# M2354 register map
File version: 1.0
Registers are 32-bit, read-write, reset 0x0 unless marked. A register's access mark holds for its fields unless they carry their own. Offsets are from the block's base; [hi:lo] are bit positions; {n}, {i} and the like mark numbered series; 'fields as' and 'values as' point back to an identical list.

## SYS (part 2 of 2) — SYS Register Map
Base 0x40000000
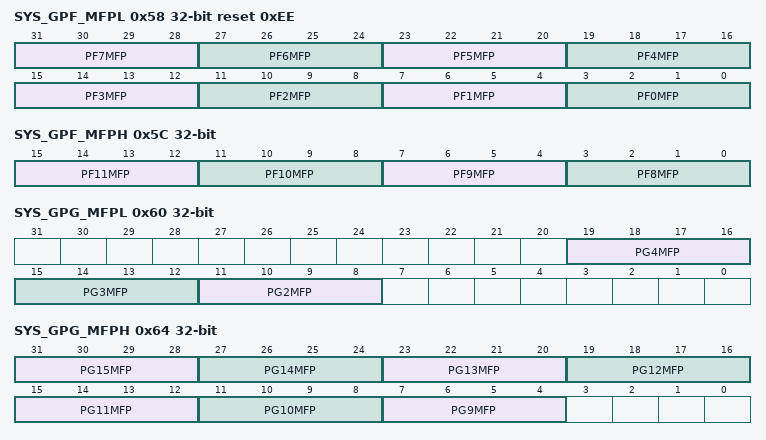
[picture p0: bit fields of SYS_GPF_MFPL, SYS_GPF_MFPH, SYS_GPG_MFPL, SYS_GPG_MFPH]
0x58 SYS_GPF_MFPL reset 0xEE — GPIOF Low Byte Multiple Function Control Register
  [31:28] PF7MFP — PF.7 Multi-function Pin Selection
    0=PF.7; 2=EBI_ADR18; 3=SC0_DAT; 4=I2S0_DO; 5=SPI0_MISO; 6=UART4_TXD; 10=TAMPER1
  [27:24] PF6MFP — PF.6 Multi-function Pin Selection
    0=PF.6; 2=EBI_ADR19; 3=SC0_CLK; 4=I2S0_LRCK; 5=SPI0_MOSI; 6=UART4_RXD; 7=EBI_nCS0; 9=SPI3_I2SMCLK; 10=TAMPER0
  [23:20] PF5MFP — PF.5 Multi-function Pin Selection
    0=PF.5; 2=UART2_RXD; 4=UART2_nCTS; 7=EPWM0_CH0; 8=BPWM0_CH4; 9=EPWM0_SYNC_OUT; 10=X32_IN; 11=EADC0_ST
  [19:16] PF4MFP — PF.4 Multi-function Pin Selection
    0=PF.4; 2=UART2_TXD; 4=UART2_nRTS; 7=EPWM0_CH1; 8=BPWM0_CH5; 10=X32_OUT
  [15:12] PF3MFP — PF.3 Multi-function Pin Selection
    0=PF.3; 2=EBI_nCS0; 3=UART0_TXD; 4=I2C0_SCL; 10=XT1_IN; 11=BPWM1_CH0
  [11:8] PF2MFP — PF.2 Multi-function Pin Selection
    0=PF.2; 2=EBI_nCS1; 3=UART0_RXD; 4=I2C0_SDA; 5=QSPI0_CLK; 10=XT1_OUT; 11=BPWM1_CH1
  [7:4] PF1MFP — PF.1 Multi-function Pin Selection
    0=PF.1; 2=UART1_RXD; 3=I2C1_SDA; 4=UART0_RXD; 12=BPWM1_CH1; 14=ICE_CLK
  [3:0] PF0MFP — PF.0 Multi-function Pin Selection
    0=PF.0; 2=UART1_TXD; 3=I2C1_SCL; 4=UART0_TXD; 12=BPWM1_CH0; 14=ICE_DAT
0x5C SYS_GPF_MFPH — GPIOF High Byte Multiple Function Control Register
  [15:12] PF11MFP — PF.11 Multi-function Pin Selection
    0=PF.11; 2=EBI_ADR14; 3=SPI2_MOSI; 6=UART5_TXD; 10=TAMPER5; 12=TM5; 13=TM3
  [11:8] PF10MFP — PF.10 Multi-function Pin Selection
    0=PF.10; 2=EBI_ADR15; 3=SC0_nCD; 4=I2S0_BCLK; 5=SPI0_I2SMCLK; 6=UART5_RXD; 10=TAMPER4
  [7:4] PF9MFP — PF.9 Multi-function Pin Selection
    0=PF.9; 2=EBI_ADR16; 3=SC0_PWR; 4=I2S0_MCLK; 5=SPI0_SS; 6=UART5_nRTS; 10=TAMPER3
  [3:0] PF8MFP — PF.8 Multi-function Pin Selection
    0=PF.8; 2=EBI_ADR17; 3=SC0_RST; 4=I2S0_DI; 5=SPI0_CLK; 6=UART5_nCTS; 10=TAMPER2
0x60 SYS_GPG_MFPL — GPIOG Low Byte Multiple Function Control Register
  [19:16] PG4MFP — PG.4 Multi-function Pin Selection
    0=PG.4; 2=EBI_ADR13; 3=SPI2_MISO; 12=TM4; 13=TM2; 15=LCD_SEG37
  [15:12] PG3MFP — PG.3 Multi-function Pin Selection
    0=PG.3; 2=EBI_ADR12; 3=SPI2_CLK; 4=I2C0_SMBSUS; 5=I2C1_SDA; 13=TM1; 15=LCD_SEG38
  [11:8] PG2MFP — PG.2 Multi-function Pin Selection
    0=PG.2; 2=EBI_ADR11; 3=SPI2_SS; 4=I2C0_SMBAL; 5=I2C1_SCL; 13=TM0; 15=LCD_SEG39
0x64 SYS_GPG_MFPH — GPIOG High Byte Multiple Function Control Register
  [31:28] PG15MFP — PG.15 Multi-function Pin Selection
    0=PG.15; 13=LCD_SEG15; 14=CLKO; 15=EADC0_ST
  [27:24] PG14MFP — PG.14 Multi-function Pin Selection
    0=PG.14; 2=EBI_AD5; 12=BPWM0_CH0; 15=LCD_SEG16
  [23:20] PG13MFP — PG.13 Multi-function Pin Selection
    0=PG.13; 2=EBI_AD4; 12=BPWM0_CH1; 15=LCD_SEG17
  [19:16] PG12MFP — PG.12 Multi-function Pin Selection
    0=PG.12; 2=EBI_AD3; 12=BPWM0_CH2; 15=LCD_SEG18
  [15:12] PG11MFP — PG.11 Multi-function Pin Selection
    0=PG.11; 2=EBI_AD2; 12=BPWM0_CH3; 15=LCD_SEG19
  [11:8] PG10MFP — PG.10 Multi-function Pin Selection
    0=PG.10; 2=EBI_AD1; 12=BPWM0_CH4; 15=LCD_SEG20
  [7:4] PG9MFP — PG.9 Multi-function Pin Selection
    0=PG.9; 2=EBI_AD0; 12=BPWM0_CH5; 15=LCD_SEG21
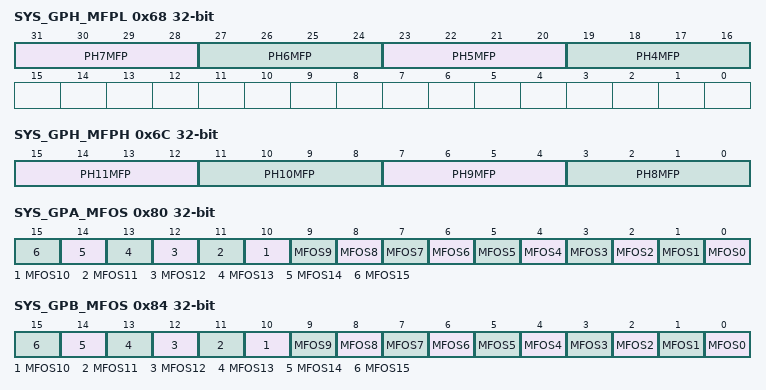
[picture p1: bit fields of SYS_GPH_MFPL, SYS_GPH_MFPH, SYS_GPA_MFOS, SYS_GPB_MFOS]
0x68 SYS_GPH_MFPL — GPIOH Low Byte Multiple Function Control Register
  [31:28] PH7MFP — PH.7 Multi-function Pin Selection
    0=PH.7; 2=EBI_ADR0; 3=SPI1_SS; 15=LCD_SEG33
  [27:24] PH6MFP — PH.6 Multi-function Pin Selection
    0=PH.6; 2=EBI_ADR1; 3=SPI1_CLK; 15=LCD_SEG34
  [23:20] PH5MFP — PH.5 Multi-function Pin Selection
    0=PH.5; 2=EBI_ADR2; 3=SPI1_MOSI; 15=LCD_SEG35
  [19:16] PH4MFP — PH.4 Multi-function Pin Selection
    0=PH.4; 2=EBI_ADR3; 3=SPI1_MISO; 15=LCD_SEG36
0x6C SYS_GPH_MFPH — GPIOH High Byte Multiple Function Control Register
  [15:12] PH11MFP — PH.11 Multi-function Pin Selection
    0=PH.11; 2=EBI_AD15; 3=QSPI0_MOSI1; 7=UART4_RXD; 8=UART0_RXD; 11=EPWM0_CH5; 15=LCD_SEG1
  [11:8] PH10MFP — PH.10 Multi-function Pin Selection
    0=PH.10; 2=EBI_AD14; 3=QSPI0_MISO1; 4=SC2_nCD; 5=I2S0_LRCK; 6=SPI1_I2SMCLK; 7=UART4_TXD; 8=UART0_TXD; 15=LCD_SEG2
  [7:4] PH9MFP — PH.9 Multi-function Pin Selection
    0=PH.9; 2=EBI_AD13; 3=QSPI0_SS; 4=SC2_RST; 5=I2S0_DO; 6=SPI1_SS; 7=UART3_nCTS; 8=I2C1_SMBSUS; 9=I2C2_SDA; 10=UART1_RXD; 15=LCD_SEG3
  [3:0] PH8MFP — PH.8 Multi-function Pin Selection
    0=PH.8; 2=EBI_AD12; 3=QSPI0_CLK; 4=SC2_PWR; 5=I2S0_DI; 6=SPI1_CLK; 7=UART3_nRTS; 8=I2C1_SMBAL; 9=I2C2_SCL; 10=UART1_TXD; 15=LCD_SEG4
0x80 SYS_GPA_MFOS — GPIOA Multiple Function Output Select Register
  [all] fields
    0=Multiple function pin output mode type is Push-pull mode; 1=Multiple function pin output mode type is Open-drain mode
  [n] MFOS{n} (n=0..15) — GPIOA-h Pin[n] Multiple Function Pin Output Mode Select. This bit used to select multiple function pin output mode type for Px.n pin.
0x84 SYS_GPB_MFOS — GPIOB Multiple Function Output Select Register
  fields as SYS_GPA_MFOS
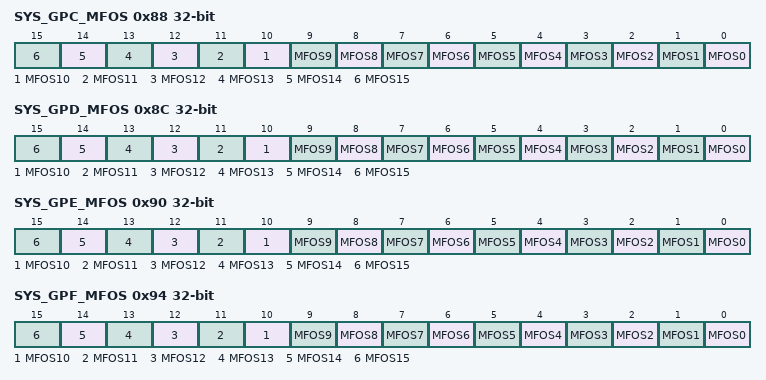
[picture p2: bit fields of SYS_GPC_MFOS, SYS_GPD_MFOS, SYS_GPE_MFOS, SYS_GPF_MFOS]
0x88 SYS_GPC_MFOS — GPIOC Multiple Function Output Select Register
  fields as SYS_GPA_MFOS
0x8C SYS_GPD_MFOS — GPIOD Multiple Function Output Select Register
  fields as SYS_GPA_MFOS
0x90 SYS_GPE_MFOS — GPIOE Multiple Function Output Select Register
  fields as SYS_GPA_MFOS
0x94 SYS_GPF_MFOS — GPIOF Multiple Function Output Select Register
  fields as SYS_GPA_MFOS
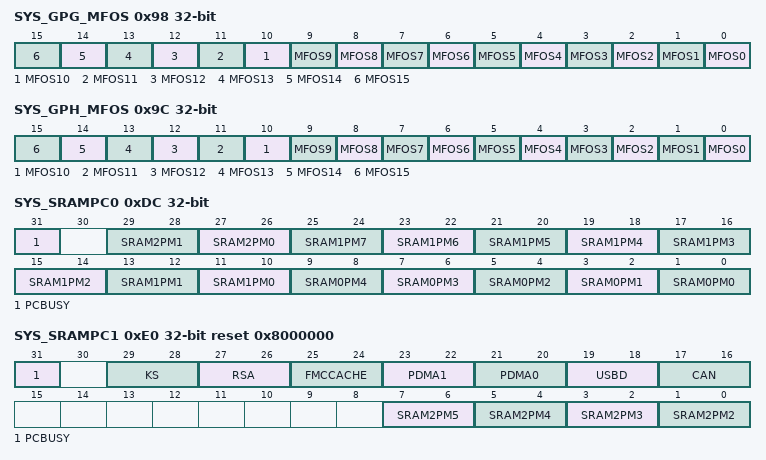
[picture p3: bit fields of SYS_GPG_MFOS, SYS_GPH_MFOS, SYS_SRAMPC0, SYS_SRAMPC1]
0x98 SYS_GPG_MFOS — GPIOG Multiple Function Output Select Register
  fields as SYS_GPA_MFOS
0x9C SYS_GPH_MFOS — GPIOH Multiple Function Output Select Register
  fields as SYS_GPA_MFOS
0xA0 SYS_VTORSET — VTOR Setting Register
  [31:10] VTORSET — VTOR Setting After SPD Wakeup (Write Protect). This is the register to set the address of vector table after chip is waked up from SPD mode. The value will be loaded to Vector Table Offset Register, which is at the address 0xE000ED08, when chip wake up from SPD mode. Note: These bits are write protected. Refer to the SYS_REGLCTL register.
0xC0 SYS_SRAMICTL — System SRAM Parity Error Interrupt Enable Control Register
  [0] PERRIEN — SRAM Parity Check Error Interrupt Enable Bit
    0=SRAM parity check error interrupt Disabled; 1=SRAM parity check error interrupt Enabled
0xC4 SYS_SRAMSTS ro (reset mask 0xFFFFFFF0) — System SRAM Parity Check Status Register
  [0] PERRIF — SRAM Parity Check Error Flag. This bit indicates the System SRAM parity error occurred. Write 1 to clear this to 0. Note: The default value depends on the content of SRAM. It is better to check this value before use it. If the default value is 1, it shall be cleared first.
    0=No System SRAM parity error; 1=System SRAM parity error occur
0xC8 SYS_SRAMEADR ro — System SRAM Parity Error Address Register
  [31:0] ERRADDR — System SRAM Parity Error Address. This register shows system SRAM parity error byte address.
0xDC SYS_SRAMPC0 — SRAM Power Mode Control Register 0
  [31] PCBUSY ro — Power Changing Busy Flag (Read Only). This bit indicate SRAM power changing.
    0=SRAM power change finish; 1=SRAM power changing
  [29:28] SRAM2PM1 — Bank2 SRAM Power Mode Select 1 (Write Protect). This field can control bank2 sram1 (16k) power mode for range 0x2002_C000 - 0x2002_FFFF. Note 1: These bits are write protected. Refer to the SYS_REGLCTL register. Note 2: Write ignore when PCBUSY is 1.
    0=Normal mode; 1=Retention mode; 2=Power shut down mode
  [27:26] SRAM2PM0 — Bank2 SRAM Power Mode Select 0 (Write Protect). This field can control bank2 sram0 (16k) power mode for range 0x2002_8000 - 0x2002_BFFF. Note 1: These bits are write protected. Refer to the SYS_REGLCTL register. Note 2: Write ignore when PCBUSY is 1.
    0=Normal mode; 1=Retention mode; 2=Power shut down mode
  [25:24] SRAM1PM7 — Bank1 SRAM Power Mode Select 7 (Write Protect). This field can control bank1 sram7 (16k) power mode for range 0x2002_4000 - 0x2002_7FFF. Note 1: These bits are write protected. Refer to the SYS_REGLCTL register. Note 2: Write ignore when PCBUSY is 1.
    0=Normal mode; 1=Retention mode; 2=Power shut down mode
  [23:22] SRAM1PM6 — Bank1 SRAM Power Mode Select 6 (Write Protect). This field can control bank1 sram6 (16k) power mode for range 0x2002_0000 - 0x2002_3FFF. Note 1: These bits are write protected. Refer to the SYS_REGLCTL register. Note 2: Write ignore when PCBUSY is 1.
    0=Normal mode; 1=Retention mode; 2=Power shut down mode
  [21:20] SRAM1PM5 — Bank1 SRAM Power Mode Select 5 (Write Protect). This field can control bank1 sram5 (16k) power mode for range 0x2001_C000 - 0x2001_FFFF. Note 1: These bits are write protected. Refer to the SYS_REGLCTL register. Note 2: Write ignore when PCBUSY is 1.
    0=Normal mode; 1=Retention mode; 2=Power shut down mode
  [19:18] SRAM1PM4 — Bank1 SRAM Power Mode Select 4 (Write Protect). This field can control bank1 sram4 (16k) power mode for range 0x2001_8000 - 0x2001_BFFF. Note 1: These bits are write protected. Refer to the SYS_REGLCTL register. Note 2: Write ignore when PCBUSY is 1.
    0=Normal mode; 1=Retention mode; 2=Power shut down mode
  [17:16] SRAM1PM3 — Bank1 SRAM Power Mode Select 3 (Write Protect). This field can control bank1 sram3 (16k) power mode for range 0x2001_4000 - 0x2001_7FFF. Note 1: These bits are write protected. Refer to the SYS_REGLCTL register. Note 2: Write ignore when PCBUSY is 1.
    0=Normal mode; 1=Retention mode; 2=Power shut down mode
  [15:14] SRAM1PM2 — Bank1 SRAM Power Mode Select 2 (Write Protect). This field can control bank1 sram2 (16k) power mode for range 0x2001_0000 - 0x2001_3FFF. Note 1: These bits are write protected. Refer to the SYS_REGLCTL register. Note 2: Write ignore when PCBUSY is 1.
    0=Normal mode; 1=Retention mode; 2=Power shut down mode
  [13:12] SRAM1PM1 — Bank1 SRAM Power Mode Select 1 (Write Protect). This field can control bank1 sram1 (16k) power mode for range 0x2000_C000 - 0x2000_FFFF. Note 1: These bits are write protected. Refer to the SYS_REGLCTL register. Note 2: Write ignore when PCBUSY is 1.
    0=Normal mode; 1=Retention mode; 2=Power shut down mode
  [11:10] SRAM1PM0 — Bank1 SRAM Power Mode Select 0 (Write Protect). This field can control bank1 sram0 (16k) power mode for range 0x2000_8000 - 0x2000_BFFF. Note 1: These bits are write protected. Refer to the SYS_REGLCTL register. Note 2: Write ignore when PCBUSY is 1.
    0=Normal mode; 1=Retention mode; 2=Power shut down mode
  [9:8] SRAM0PM4 — Bank0 SRAM Power Mode Select 4 (Write Protect). This field can control bank0 sram4 (8k) power mode for range 0x2000_6000 - 0x2000_7FFF. Note 1: These bits are write protected. Refer to the SYS_REGLCTL register. Note 2: Write ignore when PCBUSY is 1.
    0=Normal mode; 1=Retention mode; 2=Power shut down mode
  [7:6] SRAM0PM3 — Bank0 SRAM Power Mode Select 3 (Write Protect). This field can control bank0 sram3 (8k) power mode for range 0x2000_4000 - 0x2000_5FFF. Note 1: These bits are write protected. Refer to the SYS_REGLCTL register. Note 2: Write ignore when PCBUSY is 1.
    0=Normal mode; 1=Retention mode; 2=Power shut down mode
  [5:4] SRAM0PM2 — Bank0 SRAM Power Mode Select 2 (Write Protect). This field can control bank0 sram2 (8k) power mode for range 0x2000_2000 - 0x2000_3FFF. Note 1: These bits are write protected. Refer to the SYS_REGLCTL register. Note 2: Write ignore when PCBUSY is 1.
    0=Normal mode; 1=Retention mode; 2=Power shut down mode
  [3:2] SRAM0PM1 — Bank0 SRAM Power Mode Select 1 (Write Protect). This field can control bank0 sram1 (4k) power mode for range 0x2000_1000 - 0x2000_1FFF. Note 1: These bits are write protected. Refer to the SYS_REGLCTL register. Note 2: Write ignore when PCBUSY is 1.
    0=Normal mode; 1=Retention mode; 2=Power shut down mode
  [1:0] SRAM0PM0 — Bank0 SRAM Power Mode Select 0 (Write Protect). This field can control bank0 sram0 (4k) power mode for range 0x2000_0000 - 0x2000_0FFF. Note 1: These bits are write protected. Refer to the SYS_REGLCTL register. Note 2: Write ignore when PCBUSY is 1.
    0=Normal mode; 1=Retention mode; 2=Power shut down mode
0xE0 SYS_SRAMPC1 reset 0x8000000 — SRAM Power Mode Control Register 1
  [31] PCBUSY ro — Power Changing Busy Flag (Read Only). This bit indicate SRAM power changing.
    0=SRAM power change finish; 1=SRAM power changing
  [29:28] KS — Key Store SRAM Power Mode Select (Write Protect). This field can control Key Store sram power mode. Note 1: These bits are write protected. Refer to the SYS_REGLCTL register. Note 2: Write ignore when PCBUSY is 1.
    0=Normal mode; 1=Retention mode; 2=Power shut down mode
  [27:26] RSA — RSA SRAM Power Mode Select (Write Protect). This field can control RSA sram power mode. Note 1: These bits are write protected. Refer to the SYS_REGLCTL register. Note 2: Write ignore when PCBUSY is 1. Note 3: If CRPTPWREN of SYS_PSWCTL is set to 1, RSA SRAM is auto set to normal mode by hardware.
    0=Normal mode; 1=Retention mode; 2=Power shut down mode
  [25:24] FMCCACHE — FMC SRAM Power Mode Select (Write Protect). This field can control FMC cache sram power mode. Note 1: These bits are write protected. Refer to the SYS_REGLCTL register. Note 2: Write ignore when PCBUSY is 1.
    0=Normal mode; 1=Retention mode; 2=Power shut down mode
  [23:22] PDMA1 — PDMA SRAM Power Mode Select (Write Protect). This field can control PDMA1 sram power mode. Note 1: These bits are write protected. Refer to the SYS_REGLCTL register. Note 2: Write ignore when PCBUSY is 1.
    0=Normal mode; 1=Retention mode; 2=Power shut down mode
  [21:20] PDMA0 — PDMA SRAM Power Mode Select (Write Protect). This field can control PDMA0 (always secure) sram power mode. Note 1: These bits are write protected. Refer to the SYS_REGLCTL register. Note 2: Write ignore when PCBUSY is 1.
    0=Normal mode; 1=Retention mode; 2=Power shut down mode
  [19:18] USBD — USB Device SRAM Power Mode Select (Write Protect). This field can control USB device sram power mode. Note 1: These bits are write protected. Refer to the SYS_REGLCTL register. Note 2: Write ignore when PCBUSY is 1.
    0=Normal mode; 1=Retention mode; 2=Power shut down mode
  [17:16] CAN — CAN SRAM Power Mode Select (Write Protect). This field can control CAN sram power mode. Note 1: These bits are write protected. Refer to the SYS_REGLCTL register. Note 2: Write ignore when PCBUSY is 1.
    0=Normal mode; 1=Retention mode; 2=Power shut down mode
  [7:6] SRAM2PM5 — Bank2 SRAM Power Mode Select 5 (Write Protect). This field can control bank2 sram5 (16k) power mode for range 0x2003_C000 - 0x2003_FFFF. Note 1: These bits are write protected. Refer to the SYS_REGLCTL register. Note 2: Write ignore when PCBUSY is 1.
    0=Normal mode; 1=Retention mode; 2=Power shut down mode
  [5:4] SRAM2PM4 — Bank2 SRAM Power Mode Select 4 (Write Protect). This field can control bank2 sram4 (16k) power mode for range 0x2003_8000 - 0x2003_BFFF. Note 1: These bits are write protected. Refer to the SYS_REGLCTL register. Note 2: Write ignore when PCBUSY is 1.
    0=Normal mode; 1=Retention mode; 2=Power shut down mode
  [3:2] SRAM2PM3 — Bank2 SRAM Power Mode Select 3 (Write Protect). This field can control bank2 sram3 (16k) power mode for range 0x2003_4000 - 0x2003_7FFF. Note 1: These bits are write protected. Refer to the SYS_REGLCTL register. Note 2: Write ignore when PCBUSY is 1.
    0=Normal mode; 1=Retention mode; 2=Power shut down mode
  [1:0] SRAM2PM2 — Bank2 SRAM Power Mode Select 2 (Write Protect). This field can control bank2 sram2 (16k) power mode for range 0x2003_0000 - 0x2003_3FFF. Note 1: These bits are write protected. Refer to the SYS_REGLCTL register. Note 2: Write ignore when PCBUSY is 1.
    0=Normal mode; 1=Retention mode; 2=Power shut down mode
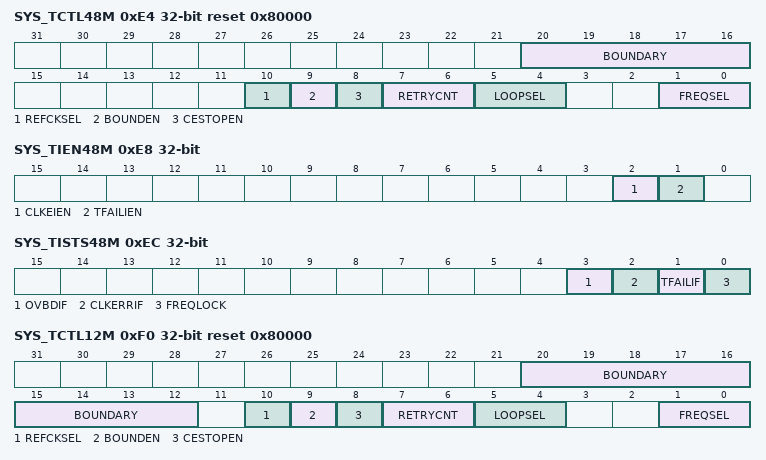
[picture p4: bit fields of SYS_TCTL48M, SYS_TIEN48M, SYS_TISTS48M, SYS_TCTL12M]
0xE4 SYS_TCTL48M reset 0x80000 — HIRC 48M Trim Control Register
  [20:16] BOUNDARY — Boundary Selection. Fill the boundary range from 0x1 to 0x31, 0x0 is reserved. Note: This field is effective only when the BOUNDEN(SYS_TCTL48M [9]) is enable.
  [10] REFCKSEL — Reference Clock Selection
    0=HIRC trim 48M reference clock is from external 32.768 kHz crystal oscillator; 1=HIRC trim 48M reference clock is from internal USB synchronous mode
  [9] BOUNDEN — Boundary Enable Bit
    0=Boundary function is disable; 1=Boundary function is enable
  [8] CESTOPEN — Clock Error Stop Enable Bit
    0=The trim operation is keep going if clock is inaccuracy; 1=The trim operation is stopped if clock is inaccuracy
  [7:6] RETRYCNT — Trim Value Update Limitation Count. This field defines that how many times the auto trim circuit will try to update the HIRC trim value before the frequency of HIRC locked. Once the HIRC locked, the internal trim value update counter will be reset. If the trim value update counter reached this limitation value and frequency of HIRC still doesn't lock, the auto trim operation will be disabled and FREQSEL will be cleared to 00.
    0=Trim retry count limitation is 64 loops; 1=Trim retry count limitation is 128 loops; 2=Trim retry count limitation is 256 loops; 3=Trim retry count limitation is 512 loops
  [5:4] LOOPSEL — Trim Calculation Loop Selection. This field defines that trim value calculation is based on how many reference clocks. Note: For example, if LOOPSEL is set as 00, auto trim circuit will calculate trim value based on the average frequency difference in 4 clocks of reference clock.
    0=Trim value calculation is based on average difference in 4 clocks of reference clock; 1=Trim value calculation is based on average difference in 8 clocks of reference clock; 2=Trim value calculation is based on average difference in 16 clocks of reference clock; 3=Trim value calculation is based on average difference in 32 clocks of reference clock
  [1:0] FREQSEL — Trim Frequency Selection. This field indicates the target frequency of 48 MHz internal high speed RC oscillator (HIRC) auto trim. During auto trim operation, if clock error detected with CESTOPEN is set to 1 or trim retry limitation count reached, this field will be cleared to 00 automatically.
    0=Disable HIRC auto trim function; 1=Enable HIRC auto trim function and trim HIRC to 48 MHz
0xE8 SYS_TIEN48M — HIRC 48M Trim Interrupt Enable Register
  [2] CLKEIEN — Clock Error Interrupt Enable Bit. This bit controls if CPU would get an interrupt while clock is inaccuracy during auto trim operation. If this bit is set to1, and CLKERRIF(SYS_TISTS48M [2]) is set during auto trim operation, an interrupt will be triggered to notify the clock frequency is inaccuracy.
    0=Disable CLKERRIF(SYS_TISTS48M [2]) status to trigger an interrupt to CPU; 1=Enable CLKERRIF(SYS_TISTS48M [2]) status to trigger an interrupt to CPU
  [1] TFAILIEN — Trim Failure Interrupt Enable Bit. This bit controls if an interrupt will be triggered while HIRC trim value update limitation count reached and HIRC frequency still not locked on target frequency set by FREQSEL(SYS_TCTL48M[1:0]). If this bit is high and TFAILIF(SYS_TSTS48M [1]) is set during auto trim operation, an interrupt will be triggered to notify that HIRC trim value update limitation count was reached.
    0=Disable TFAILIF(SYS_TISTS48M [1]) status to trigger an interrupt to CPU; 1=Enable TFAILIF(SYS_TISTS48M[1]) status to trigger an interrupt to CPU
0xEC SYS_TISTS48M — HIRC 48M Trim Interrupt Status Register
  [3] OVBDIF — Over Boundary Status. When the over boundary function is set, if there occurs the over boundary condition, this flag will be set. Note: Write 1 to clear this flag.
    0=Over boundary condition did not occur; 1=Over boundary condition occurred
  [2] CLKERRIF — Clock Error Interrupt Status. When the frequency of 32.768 kHz external low speed crystal oscillator (LXT) or 48 MHz internal high speed RC oscillator (HIRC) is shift larger to unreasonable value, this bit will be set and to be an indicate that clock frequency is inaccuracy. Once this bit is set to 1, the auto trim operation stopped and FREQSEL(SYS_TCTL48M[1:0]) will be cleared to 00 by hardware automatically if CESTOPEN(SYS_TCTL48M[8]) is set to 1. If this bit is set and CLKEIEN(SYS_TIEN48M[2]) is high, an interrupt will be triggered to notify the clock frequency is inaccuracy. Write 1 to clear this to 0.
    0=Clock frequency is accurate; 1=Clock frequency is inaccurate
  [1] TFAILIF — Trim Failure Interrupt Status. This bit indicates that HIRC trim value update limitation count reached and the HIRC clock frequency is still not locked. Once this bit is set, the auto trim operation stopped and FREQSEL(SYS_TCTL48M[1:0]) will be cleared to 00 by hardware automatically. If this bit is set and TFAILIEN(SYS_TIEN48M[1]) is high, an interrupt will be triggered to notify that HIRC trim value update limitation count was reached. Write 1 to clear this to 0.
    0=Trim value update limitation count does not reach; 1=Trim value update limitation count reached and HIRC frequency still not locked
  [0] FREQLOCK — HIRC Frequency Lock Status. This bit indicates the HIRC frequency is locked. This is a status bit and doesn't trigger any interrupt. Write 1 to clear this to 0. This bit will be set automatically, if the frequency is lock and the RC_TRIM is enabled.
    0=The internal high-speed oscillator frequency doesn't lock at 48 MHz yet; 1=The internal high-speed oscillator frequency locked at 48 MHz
0xF0 SYS_TCTL12M reset 0x80000 — HIRC 12M Trim Control Register
  [20:12] BOUNDARY — Boundary Selection. Fill the boundary range from 0x1 to 0x31, 0x0 is reserved. Note: This field is effective only when the BOUNDEN(SYS_TCTL12M[9]) is enabled.
  [10] REFCKSEL — Reference Clock Selection
    0=HIRC trim reference clock is from external 32.768 kHz crystal oscillator; 1=HIRC trim reference clock is from internal USB synchronous mode
  [9] BOUNDEN — Boundary Enable Bit
    0=Boundary function Disabled; 1=Boundary function Enabled
  [8] CESTOPEN — Clock Error Stop Enable Bit
    0=The trim operation keeps going if clock is inaccurate; 1=The trim operation is stopped if clock is inaccurate
  [7:6] RETRYCNT — Trim Value Update Limitation Count. This field defines that how many times the auto trim circuit will try to update the HIRC trim value before the frequency of HIRC locked. Once the HIRC locked, the internal trim value update counter will be reset. If the trim value update counter reached this limitation value and frequency of HIRC still doesn't lock, the auto trim operation will be disabled and FREQSEL will be cleared to 00.
    values as SYS_TCTL48M.RETRYCNT
  [5:4] LOOPSEL — Trim Calculation Loop Selection. This field defines that trim value calculation is based on how many reference clocks. Note: For example, if LOOPSEL is set as 00, auto trim circuit will calculate trim value based on the average frequency difference in 4 clocks of reference clock.
    values as SYS_TCTL48M.LOOPSEL
  [1:0] FREQSEL — Trim Frequency Selection. This field indicates the target frequency of 12 MHz internal high speed RC oscillator (HIRC) auto trim. During auto trim operation, if clock error detected with CESTOPEN is set to 1 or trim retry limitation count reached, this field will be cleared to 00 automatically.
    0=Disable HIRC auto trim function; 1=Enable HIRC auto trim function and trim HIRC to 12 MHz
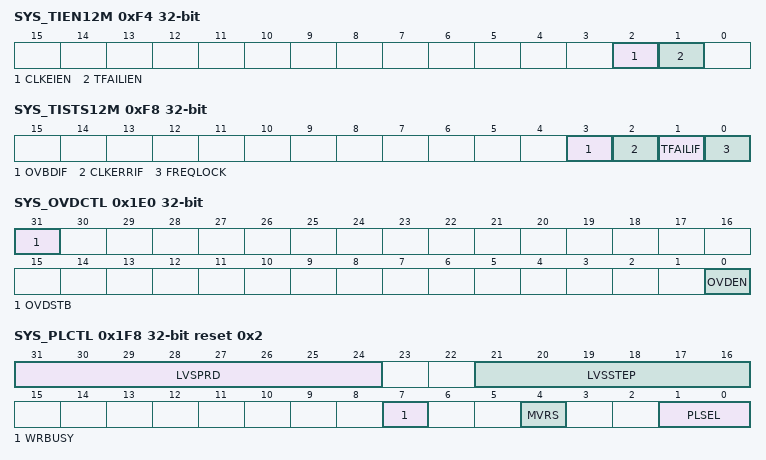
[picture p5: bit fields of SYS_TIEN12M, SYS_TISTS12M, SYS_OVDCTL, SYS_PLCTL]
0xF4 SYS_TIEN12M — HIRC 12M Trim Interrupt Enable Register
  [2] CLKEIEN — Clock Error Interrupt Enable Bit. This bit controls if CPU would get an interrupt while clock is inaccuracy during auto trim operation. If this bit is set to1, and CLKERRIF(SYS_TISTS12M[2]) is set during auto trim operation, an interrupt will be triggered to notify the clock frequency is inaccuracy.
    0=Disable CLKERRIF(SYS_TISTS12M[2]) status to trigger an interrupt to CPU; 1=Enable CLKERRIF(SYS_TISTS12M[2]) status to trigger an interrupt to CPU
  [1] TFAILIEN — Trim Failure Interrupt Enable Bit. This bit controls if an interrupt will be triggered while HIRC trim value update limitation count reached and HIRC frequency still not locked on target frequency set by FREQSEL(SYS_TCTL12M[1:0]). If this bit is high and TFAILIF(SYS_TSTS12M[1]) is set during auto trim operation, an interrupt will be triggered to notify that HIRC trim value update limitation count was reached.
    0=Disable TFAILIF(SYS_TISTS12M[1]) status to trigger an interrupt to CPU; 1=Enable TFAILIF(SYS_TISTS12M[1]) status to trigger an interrupt to CPU
0xF8 SYS_TISTS12M — HIRC 12M Trim Interrupt Status Register
  [3] OVBDIF — Over Boundary Status. When the over boundary function is set, if there occurs the over boundary condition, this flag will be set. Note: Write 1 to clear this flag.
    values as SYS_TISTS48M.OVBDIF
  [2] CLKERRIF — Clock Error Interrupt Status. When the frequency of 32.768 kHz external low speed crystal oscillator (LXT) or 12 MHz internal high speed RC oscillator (HIRC) is shift larger to unreasonable value, this bit will be set and to be an indicate that clock frequency is inaccuracy. Once this bit is set to 1, the auto trim operation stopped and FREQSEL(SYS_TCTL12M[1:0]) will be cleared to 00 by hardware automatically if CESTOPEN(SYS_TCTL12M[8]) is set to 1. If this bit is set and CLKEIEN(SYS_IRCTIEN[2]) is high, an interrupt will be triggered to notify the clock frequency is inaccuracy. Write 1 to clear this to 0.
    values as SYS_TISTS48M.CLKERRIF
  [1] TFAILIF — Trim Failure Interrupt Status. This bit indicates that HIRC trim value update limitation count reached and the HIRC clock frequency still doesn't be locked. Once this bit is set, the auto trim operation stopped and FREQSEL(SYS_TCTL12M[1:0]) will be cleared to 00 by hardware automatically. If this bit is set and TFAILIEN(SYS_TIEN12M[1]) is high, an interrupt will be triggered to notify that HIRC trim value update limitation count was reached. Write 1 to clear this to 0.
    values as SYS_TISTS48M.TFAILIF
  [0] FREQLOCK — HIRC Frequency Lock Status. This bit indicates the HIRC frequency is locked. This is a status bit and doesn't trigger any interrupt. Write 1 to clear this to 0. This bit will be set automatically, if the frequency is lock and the RC_TRIM is enabled.
    0=The internal high-speed oscillator frequency is not locked at 12 MHz yet; 1=The internal high-speed oscillator frequency locked at 12 MHz
0x100 SYS_REGLCTL — Register Lock Control Register
  [7:0] REGLCTL — Register Lock Control Code. Some registers have write-protection function. Writing these registers have to disable the protected function by writing the sequence value '59h', '16h', '88h' to this field. After this sequence is completed, the REGLCTL bit will be set to 1 and write-protection registers can be normal write. REGLCTL[0]. Register Lock Control Disable Index
    0=Write-protection Enabled for writing protected registers. Any write to the protected register is ignored; 1=Write-protection Disabled for writing protected registers
0x1D8 SYS_CPUCFG — CPU General Configuration Register
  [0] INTRTEN — CPU Interrupt Realtime Enable Bit. When this bit is 0, the latency of CPU entering interrupt service routine (ISR) will be various but shorter. When this bit is 1, the latency of CPU entering ISR will be kept constant.
    0=CPU Interrupt Realtime Disabled; 1=CPU Interrupt Realtime Enabled
0x1DC SYS_BATLDCTL — Battery Loss Detector Control Register
  [0] BATLDEN — Battery Loss Detector Enable Bit (Write Protect). Note: This bit is write protected. Refer to the SYS_REGLCTL register.
    0=Battery Loss Detector Disabled; 1=Battery Loss Detector Enabled
0x1E0 SYS_OVDCTL — Over Voltage Detector Control Register
  [31] OVDSTB ro — Over Voltage Detector Stable Flag (Read Only)
    0=Over voltage detector not stable; 1=Over voltage detector stable
  [0] OVDEN — Over Voltage Detector Enable Bit (Write Protect). Note: This bit is write protected. Refer to the SYS_REGLCTL register.
    0=Over voltage detector Disabled; 1=Over voltage detector Enabled
0x1EC SYS_PORCTL1 (reset mask 0xFFFFFF00) — Power-on Reset Controller Register 1
  [15:0] POROFF — Power-on Reset Enable Bit (Write Protect). When powered on, the POR circuit generates a reset signal to reset the whole chip function, but noise on the power may cause the POR active again. User can disable internal POR circuit to avoid unpredictable noise to cause chip reset by writing 0x5AA5 to this field. The POR function will be active again when this field is set to another value or chip is reset by other reset source, including: nRESET, Watchdog, LVR reset, BOD reset, ICE reset command and the software-chip reset function. Note: These bits are write protected. Refer to the SYS_REGLCTL register.
0x1F4 SYS_PSWCTL — Power Switch Control Register
  [12] CRPTPWREN — Cryptographic Accelerator Power Switch Enable Bit (Write Protect). Note 1: If this bit is set 1, RSA of SYS_SRAMPC1 is set to normal mode by hardware. Note 2: Write ignored when PCBUSY(SYS_SRAMPC1[31]) is 1. Note 3: This bit is write protected. Refer to the SYS_REGLCTL register.
    0=Cryptographic accelerator power supply Disabled; 1=Cryptographic accelerator power supply Enabled
0x1F8 SYS_PLCTL reset 0x2 — Power Level Control Register
  [31:24] LVSPRD — LDO Voltage Scaling Period (Write Protect). The LVSPRD value is the period of each LDO voltage rising step. Note: These bits are write protected. Refer to the SYS_REGLCTL register.
  [21:16] LVSSTEP — LDO Voltage Scaling Step (Write Protect). The LVSSTEP value is LDO voltage rising step. Note: These bits are write protected. Refer to the SYS_REGLCTL register.
  [7] WRBUSY ro — Write Busy Flag (Read Only). If SYS_PLCTL be written, this bit be asserted automatic by hardware, and be de-asserted when write procedure finish.
    0=SYS_PLCTL register is ready for write operation; 1=SYS_PLCTL register is busy on the last write operation. Other write operations are ignored
  [4] MVRS — Main Voltage Regulator Type Select (Write Protect). This bit field sets main voltage regulator type. Note 1: This bit is write protected. Refer to the SYS_REGLCTL register. Note 2: This bit not be reset when wake-up from Standby Power-down mode(SPD).
    0=Set main voltage regulator to LDO; 1=Set main voltage regulator to DCDC
  [1:0] PLSEL — Power Level Select (Write Protect). Note 1: These bits are write protected. Refer to the SYS_REGLCTL register. Note 2: These bits not be reset when wake-up from Standby Power-down mode (SPD).
    0=Set to Power level 0 (PL0); 1=Set to Power level 1 (PL1); 2=Set to Power level 2 (PL2). (default); 3=Set to Power level 3 (PL3)
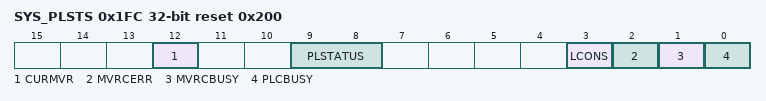
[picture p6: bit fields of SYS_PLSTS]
0x1FC SYS_PLSTS reset 0x200 (reset mask 0xFFFFFFF0) — Power Level Status Register
  [12] CURMVR ro — Current Main Voltage Regulator Type (Read Only). This bit field reflects current main voltage regulator type.
    0=Current main voltage regulator in active and Idle mode is LDO; 1=Current main voltage regulator in active and Idle mode is DCDC
  [9:8] PLSTATUS ro — Power Level Status (Read Only). This bit field reflect the current power level.
    {v}=Power level is PL{v} (v=0..3)
  [3] LCONS ro — Inductor for DCDC Connect Status (Read Only). Note: This bit is 1 when main voltage regulator is LDO.
    0=Inductor connect between Vsw and LDO_CAP pin; 1=No Inductor connect between Vsw and LDO_CAP pin
  [2] MVRCERR — Main Voltage Regulator Type Change Error Bit (Write Protect). This bit is set to 1 when main voltage regulator type change from LDO to DCDC error, the following conditions will cause change errors: System changed to DC-DC mode but LDO change voltage process not finish. Detect inductor failed. Note 1: This bit is write protected. Refer to the SYS_REGLCTL register. Note 2: Write 1 to clear this bit to 0.
    0=No main voltage regulator type change error; 1=Main voltage regulator type change to DCDC error occurred
  [1] MVRCBUSY ro — Main Voltage Regulator Type Change Busy Bit (Read Only). This bit is set by hardware when main voltage regulator type is changing. After main voltage regulator type change is completed, this bit will be cleared automatically by hardware.
    0=Main voltage regulator type change is completed; 1=Main voltage regulator type change is ongoing
  [0] PLCBUSY ro — Power Level Change Busy Bit (Read Only). This bit is set by hardware when power level is changing. After power level change is completed, this bit will be cleared automatically by hardware.
    0=Power level change is completed; 1=Power level change is ongoing
